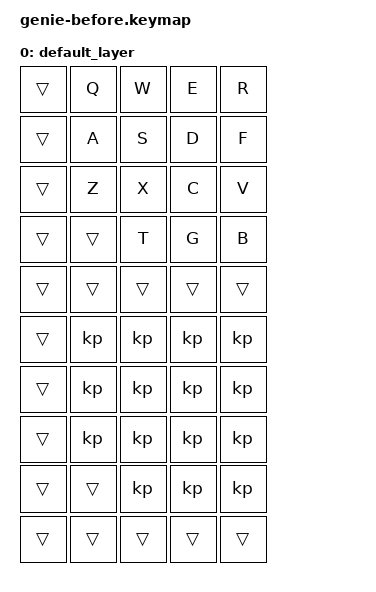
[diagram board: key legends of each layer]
    #include <behaviors.dtsi>
#include <dt-bindings/zmk/keys.h>

/ {
    keymap {
        compatible = "zmk,keymap";

        default_layer { // Layer 0
            /*  Q       W       E       R       T 
                Y*/

            bindings = <
                //0,0   0,1     0,2     0,3     0,4
                &trans   &kp Q   &kp W   &kp E   &kp R 

                //1,0   1,1     1,2     1,3     1,4
                &trans   &kp A   &kp S   &kp D   &kp F

                //2,0   2,1     2,2     2,3     2,4
                &trans   &kp Z   &kp X   &kp C   &kp V 

                //3,0   3,1     3,2     3,3     3,4
                &trans  &trans   &kp T   &kp G   &kp B

                //4,0   4,1     4,2     4,3     4,4
                &trans    &trans   &trans   &trans   &trans


                //5,5   5,6     5,7     5,8     5,9
                &trans    &kp   &kp   &kp   &kp 

                //6,5   6,6     6,7     6,8     6,9
                &trans    &kp   &kp   &kp   &kp 

                //7,5   7,6     7,7     7,8     7,9
                &trans    &kp   &kp   &kp   &kp

                //8,5   8,6     8,7     8,8     8,9 
                &trans    &trans   &kp   &kp   &kp 

                //9,5   9,6     9,7     9,8     9,9 
                &trans    &trans   &trans   &trans   &trans
 

            >;
        };
    };
 };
